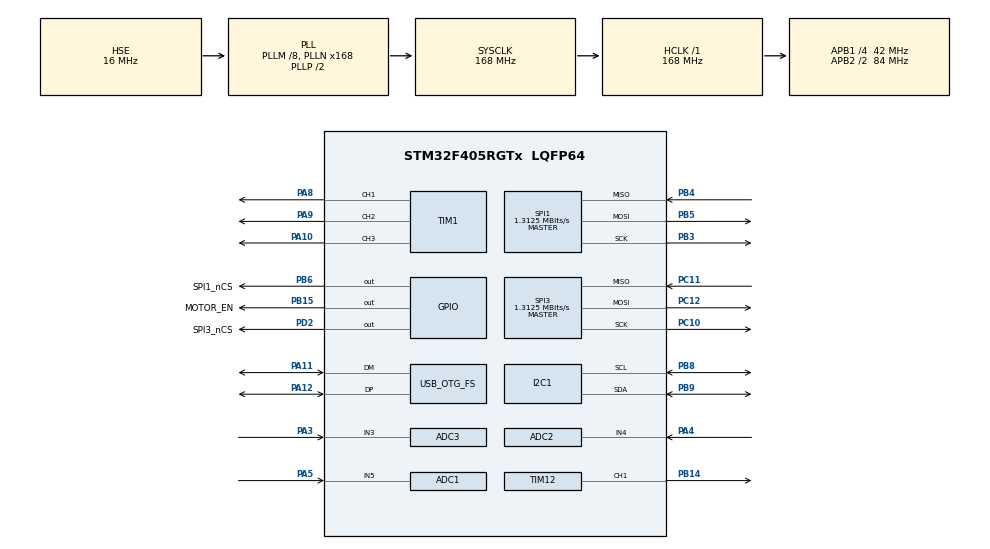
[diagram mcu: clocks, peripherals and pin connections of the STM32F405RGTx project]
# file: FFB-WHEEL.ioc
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ADC1.Channel-2\#ChannelRegularConversion=ADC_CHANNEL_VREFINT
ADC1.Channel-5\#ChannelInjectedConversion=ADC_CHANNEL_5
ADC1.DMAContinuousRequests=ENABLE
ADC1.EOCSelection=ADC_EOC_SEQ_CONV
ADC1.ExternalTrigConv=ADC_SOFTWARE_START
ADC1.ExternalTrigInjecConv=ADC_EXTERNALTRIGINJECCONV_T1_CC4
ADC1.InjNumberOfConversion=1
ADC1.InjectedOffset-5\#ChannelInjectedConversion=0
ADC1.InjectedRank-5\#ChannelInjectedConversion=1
ADC1.Mode=ADC_TRIPLEMODE_REGSIMULT_INJECSIMULT
ADC1.NbrOfConversion=1
ADC1.NbrOfConversionFlag=1
ADC1.Rank-2\#ChannelRegularConversion=1
ADC1.SamplingTime-2\#ChannelRegularConversion=ADC_SAMPLETIME_15CYCLES
ADC1.SamplingTime-5\#ChannelInjectedConversion=ADC_SAMPLETIME_15CYCLES
ADC1.master=1
ADC2.Channel-0\#ChannelRegularConversion=ADC_CHANNEL_4
ADC2.DMAAccessMode=ADC_DMAACCESSMODE_1
ADC2.Mode=ADC_TRIPLEMODE_REGSIMULT_INJECSIMULT
ADC2.NbrOfConversionFlag=1
ADC2.Rank-0\#ChannelRegularConversion=1
ADC2.SamplingTime-0\#ChannelRegularConversion=ADC_SAMPLETIME_15CYCLES
ADC3.Channel-0\#ChannelRegularConversion=ADC_CHANNEL_3
ADC3.DMAAccessMode=ADC_DMAACCESSMODE_1
ADC3.Mode=ADC_TRIPLEMODE_REGSIMULT_INJECSIMULT
ADC3.NbrOfConversionFlag=1
ADC3.Rank-0\#ChannelRegularConversion=1
ADC3.SamplingTime-0\#ChannelRegularConversion=ADC_SAMPLETIME_3CYCLES
Dma.ADC1.0.Direction=DMA_PERIPH_TO_MEMORY
Dma.ADC1.0.FIFOMode=DMA_FIFOMODE_DISABLE
Dma.ADC1.0.Instance=DMA2_Stream0
Dma.ADC1.0.MemDataAlignment=DMA_MDATAALIGN_HALFWORD
Dma.ADC1.0.MemInc=DMA_MINC_ENABLE
Dma.ADC1.0.Mode=DMA_CIRCULAR
Dma.ADC1.0.PeriphDataAlignment=DMA_PDATAALIGN_HALFWORD
Dma.ADC1.0.PeriphInc=DMA_PINC_DISABLE
Dma.ADC1.0.Priority=DMA_PRIORITY_MEDIUM
Dma.Request0=ADC1
Mcu.Family=STM32F4
Mcu.Name=STM32F405RGTx
Mcu.Package=LQFP64
Mcu.UserConstants=TIM_BASE_PERIOD,3499;ADC_TRIGGER_DUTY_CYCLE,50
NVIC.ADC_IRQn=true\:0\:0\:false\:false\:true\:true\:true
NVIC.DMA2_Stream0_IRQn=true\:0\:0\:false\:false\:true\:false\:true
NVIC.OTG_FS_IRQn=true\:0\:0\:false\:false\:true\:false\:true
NVIC.PriorityGroup=NVIC_PRIORITYGROUP_4
NVIC.TIM6_DAC_IRQn=true\:0\:0\:false\:false\:true\:true\:true
NVIC.TIM7_IRQn=true\:0\:0\:false\:false\:true\:true\:true
NVIC.TIM8_TRG_COM_TIM14_IRQn=true\:0\:0\:false\:false\:true\:false\:true
NVIC.TimeBase=TIM8_TRG_COM_TIM14_IRQn
NVIC.TimeBaseIP=TIM14
PA10.Signal=S_TIM1_CH3
PA11.Mode=Device_Only
PA11.Signal=USB_OTG_FS_DM
PA12.Mode=Device_Only
PA12.Signal=USB_OTG_FS_DP
PA13.Mode=Serial_Wire
PA13.Signal=SYS_JTMS-SWDIO
PA14.Mode=Serial_Wire
PA14.Signal=SYS_JTCK-SWCLK
PA3.Signal=ADCx_IN3
PA4.Signal=ADCx_IN4
PA5.Signal=ADCx_IN5
PA8.Signal=S_TIM1_CH1
PA9.Signal=S_TIM1_CH2
PB14.Signal=S_TIM12_CH1
PB15.GPIO_Label=MOTOR_EN
PB15.Signal=GPIO_Output
PB3.Mode=Full_Duplex_Master
PB3.Signal=SPI1_SCK
PB4.Mode=Full_Duplex_Master
PB4.Signal=SPI1_MISO
PB5.Mode=Full_Duplex_Master
PB5.Signal=SPI1_MOSI
PB6.GPIO_Label=SPI1_nCS
PB6.GPIO_Speed=GPIO_SPEED_FREQ_VERY_HIGH
PB6.Signal=GPIO_Output
PB8.Mode=I2C
PB8.Signal=I2C1_SCL
PB9.Mode=I2C
PB9.Signal=I2C1_SDA
PC10.Mode=Full_Duplex_Master
PC10.Signal=SPI3_SCK
PC11.Mode=Full_Duplex_Master
PC11.Signal=SPI3_MISO
PC12.Mode=Full_Duplex_Master
PC12.Signal=SPI3_MOSI
PD2.GPIO_Label=SPI3_nCS
PD2.GPIO_Speed=GPIO_SPEED_FREQ_VERY_HIGH
PD2.Signal=GPIO_Output
PH0-OSC_IN.Mode=HSE-External-Oscillator
PH0-OSC_IN.Signal=RCC_OSC_IN
PH1-OSC_OUT.Mode=HSE-External-Oscillator
PH1-OSC_OUT.Signal=RCC_OSC_OUT
ProjectManager.HeapSize=0x200
ProjectManager.StackSize=0x400
ProjectManager.TargetToolchain=STM32CubeIDE
RCC.48MHZClocksFreq_Value=48000000
RCC.AHBFreq_Value=168000000
RCC.APB1CLKDivider=RCC_HCLK_DIV4
RCC.APB1Freq_Value=42000000
RCC.APB1TimFreq_Value=84000000
RCC.APB2CLKDivider=RCC_HCLK_DIV2
RCC.APB2Freq_Value=84000000
RCC.APB2TimFreq_Value=168000000
RCC.CortexFreq_Value=168000000
RCC.HCLKFreq_Value=168000000
RCC.HSE_VALUE=16000000
RCC.HSI_VALUE=16000000
RCC.LSE_VALUE=32768
RCC.PLLM=8
RCC.PLLN=168
RCC.PLLQ=7
RCC.SYSCLKFreq_VALUE=168000000
RCC.SYSCLKSource=RCC_SYSCLKSOURCE_PLLCLK
RCC.VCOOutputFreq_Value=336000000
SH.ADCx_IN3.0=ADC3_IN3,IN3
SH.ADCx_IN4.0=ADC2_IN4,IN4
SH.ADCx_IN5.0=ADC1_IN5,IN5
SH.S_TIM12_CH1.0=TIM12_CH1,PWM Generation1 CH1
SH.S_TIM1_CH1.0=TIM1_CH1,PWM Generation1 CH1
SH.S_TIM1_CH2.0=TIM1_CH2,PWM Generation2 CH2
SH.S_TIM1_CH3.0=TIM1_CH3,PWM Generation3 CH3
SPI1.BaudRatePrescaler=SPI_BAUDRATEPRESCALER_64
SPI1.CLKPhase=SPI_PHASE_2EDGE
SPI1.CalculateBaudRate=1.3125 MBits/s
SPI1.DataSize=SPI_DATASIZE_16BIT
SPI1.Direction=SPI_DIRECTION_2LINES
SPI1.Mode=SPI_MODE_MASTER
SPI1.VirtualType=VM_MASTER
SPI3.BaudRatePrescaler=SPI_BAUDRATEPRESCALER_32
SPI3.CLKPhase=SPI_PHASE_2EDGE
SPI3.CalculateBaudRate=1.3125 MBits/s
SPI3.DataSize=SPI_DATASIZE_16BIT
SPI3.Direction=SPI_DIRECTION_2LINES
SPI3.FirstBit=SPI_FIRSTBIT_LSB
SPI3.Mode=SPI_MODE_MASTER
SPI3.VirtualType=VM_MASTER
TIM1.AutoReloadPreload=TIM_AUTORELOAD_PRELOAD_ENABLE
TIM1.Channel-PWM\ Generation1\ CH1=TIM_CHANNEL_1
TIM1.Channel-PWM\ Generation2\ CH2=TIM_CHANNEL_2
TIM1.Channel-PWM\ Generation3\ CH3=TIM_CHANNEL_3
TIM1.Channel-PWM\ Generation4\ No\ Output=TIM_CHANNEL_4
TIM1.CounterMode=TIM_COUNTERMODE_CENTERALIGNED3
TIM1.Period=TIM_BASE_PERIOD
TIM1.Pulse-PWM\ Generation4\ No\ Output=ADC_TRIGGER_DUTY_CYCLE
TIM1.TIM_MasterOutputTrigger=TIM_TRGO_OC4REF
TIM12.AutoReloadPreload=TIM_AUTORELOAD_PRELOAD_ENABLE
TIM12.Channel-PWM\ Generation1\ CH1=TIM_CHANNEL_1
TIM12.Period=TIM_BASE_PERIOD
TIM6.Period=TIM_BASE_PERIOD
TIM6.TIM_MasterOutputTrigger=TIM_TRGO_UPDATE
TIM7.Period=TIM_BASE_PERIOD
TIM7.Prescaler=99
TIM7.TIM_MasterOutputTrigger=TIM_TRGO_UPDATE
USB_DEVICE.CLASS_NAME_FS=CUSTOM_HID
USB_DEVICE.VirtualMode-CUSTOM_HID_FS=CustomHid
USB_DEVICE.VirtualModeFS=Custom_Hid_FS
USB_OTG_FS.VirtualMode=Device_Only
VP_ADC1_Vref_Input.Mode=IN-Vrefint
VP_SYS_VS_tim14.Mode=TIM14
VP_TIM1_VS_no_output4.Mode=PWM Generation4 No Output
VP_TIM6_VS_ClockSourceINT.Mode=Enable_Timer
VP_TIM7_VS_ClockSourceINT.Mode=Enable_Timer
VP_USB_DEVICE_VS_USB_DEVICE_CUSTOM_HID_FS.Mode=CUSTOM_HID_FS
board=custom

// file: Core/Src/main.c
/* USER CODE BEGIN Header */
/**
  ******************************************************************************
  * @file           : main.c
  * @brief          : Main program body
  ******************************************************************************
  * @attention
  *
  * <h2><center>&copy; Copyright (c) 2020 STMicroelectronics.
  * All rights reserved.</center></h2>
  *
  * This software component is licensed by ST under BSD 3-Clause license,
  * the "License"; You may not use this file except in compliance with the
  * License. You may obtain a copy of the License at:
  *                        opensource.org/licenses/BSD-3-Clause
  *
  ******************************************************************************
  */
/* USER CODE END Header */
#include "main.h"
#include "adc.h"
#include "dma.h"
#include "i2c.h"
#include "spi.h"
#include "tim.h"
#include "usb_device.h"
#include "gpio.h"

/* USER CODE BEGIN Includes */
#include "common_resources.h"
/* USER CODE END Includes */

void SystemClock_Config(void);

int main(void)
{

  /* MCU Configuration--------------------------------------------------------*/

  /* Reset of all peripherals, Initializes the Flash interface and the Systick. */
  HAL_Init();

  /* Configure the system clock */
  SystemClock_Config();

  /* Initialize all configured peripherals */
  MX_GPIO_Init();
  MX_DMA_Init();
  MX_ADC1_Init();
  MX_TIM1_Init();
  MX_I2C1_Init();
  MX_USB_DEVICE_Init();
  MX_TIM6_Init();
  MX_TIM7_Init();
  MX_ADC2_Init();
  MX_ADC3_Init();
  MX_TIM12_Init();
  MX_SPI1_Init();
  MX_SPI3_Init();
  /* USER CODE BEGIN 2 */
    StartDevice();
  /* USER CODE END 2 */

  /* Infinite loop */
  /* USER CODE BEGIN WHILE */
  while (1)
  {
//      HAL_GPIO_TogglePin(SPI1_nCS_GPIO_Port, SPI1_nCS_Pin);
//      HAL_Delay(10);
      UpdateDevice();
    /* USER CODE END WHILE */

  }
}

void SystemClock_Config(void)
{
  RCC_OscInitTypeDef RCC_OscInitStruct = {0};
  RCC_ClkInitTypeDef RCC_ClkInitStruct = {0};

  /** Configure the main internal regulator output voltage
  */
  __HAL_RCC_PWR_CLK_ENABLE();
  __HAL_PWR_VOLTAGESCALING_CONFIG(PWR_REGULATOR_VOLTAGE_SCALE1);
  /** Initializes the RCC Oscillators according to the specified parameters
  * in the RCC_OscInitTypeDef structure.
  */
  RCC_OscInitStruct.OscillatorType = RCC_OSCILLATORTYPE_HSE;
  RCC_OscInitStruct.HSEState = RCC_HSE_ON;
  RCC_OscInitStruct.PLL.PLLState = RCC_PLL_ON;
  RCC_OscInitStruct.PLL.PLLSource = RCC_PLLSOURCE_HSE;
  RCC_OscInitStruct.PLL.PLLM = 8;
  RCC_OscInitStruct.PLL.PLLN = 168;
  RCC_OscInitStruct.PLL.PLLP = RCC_PLLP_DIV2;
  RCC_OscInitStruct.PLL.PLLQ = 7;
  if (HAL_RCC_OscConfig(&RCC_OscInitStruct) != HAL_OK)
  {
    Error_Handler();
  }
  /** Initializes the CPU, AHB and APB buses clocks
  */
  RCC_ClkInitStruct.ClockType = RCC_CLOCKTYPE_HCLK|RCC_CLOCKTYPE_SYSCLK
                              |RCC_CLOCKTYPE_PCLK1|RCC_CLOCKTYPE_PCLK2;
  RCC_ClkInitStruct.SYSCLKSource = RCC_SYSCLKSOURCE_PLLCLK;
  RCC_ClkInitStruct.AHBCLKDivider = RCC_SYSCLK_DIV1;
  RCC_ClkInitStruct.APB1CLKDivider = RCC_HCLK_DIV4;
  RCC_ClkInitStruct.APB2CLKDivider = RCC_HCLK_DIV2;

  if (HAL_RCC_ClockConfig(&RCC_ClkInitStruct, FLASH_LATENCY_5) != HAL_OK)
  {
    Error_Handler();
  }
}

void HAL_TIM_PeriodElapsedCallback(TIM_HandleTypeDef *htim)
{
  /* USER CODE BEGIN Callback 0 */
    PeriodElapsedCallback(htim);
  /* USER CODE END Callback 0 */
  if (htim->Instance == TIM14) {
    HAL_IncTick();
  }
}

void Error_Handler(void)
{
}

/************************ (C) COPYRIGHT STMicroelectronics *****END OF FILE****/
